# a34g43x register map
Vendor: ABOV Semiconductor Co., Ltd.; File version: 1.0
CPU: CM4 r0p1, little endian, MPU, FPU, VTOR, 4 interrupt priority bits
Registers are 32-bit, read-write, reset 0x0 unless marked. A register's access mark holds for its fields unless they carry their own. Offsets are from the block's base; [hi:lo] are bit positions; {n}, {i} and the like mark numbered series.

## I2C — Inter-Integrated Circuit
Base 0x5000A000
Same registers: I2C0 0x4000A000, I2C1 0x4000A100, I2C2 0x4000A200, I2C3 0x4000A300
0x00 DR reset 0xFF — I2Cn Data Register
  [7:0] ICDR — The I2CnDR Transmit buffer and Receive buffer share the same I/O address with this DATA register. The Transmit Data Buffer is the destination for data written to the I2CnDR register. Reading the I2CnDR register returns the contents of the Receive Buffer.
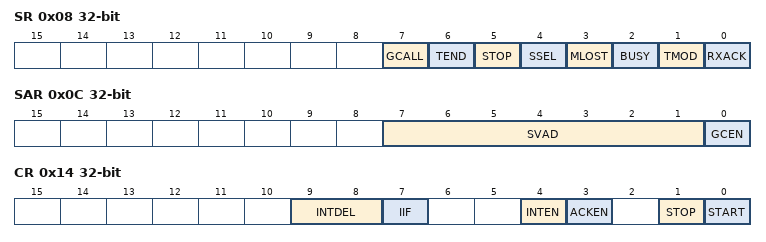
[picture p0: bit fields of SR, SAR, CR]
0x08 SR — I2Cn Status Register
  [7] GCALL — This bit has different meaning depending on whether I2C is master or slave. When I2C is a master, this bit represents whether it received AACK (address ACK) from slave.
  [6] TEND — This bit is set when 1-byte of data is transferred completely.
  [5] STOP — This bit is set when a STOP condition is detected.
  [4] SSEL — This bit is set when I2C is addressed by other master.
  [3] MLOST — This bit represents the result of bus arbitration in master mode.
  [2] BUSY — This bit reflects bus status.
  [1] TMOD ro — This bit is used to indicate whether I2C is transmitter or receiver.
  [0] RXACK — This bit shows the state of ACK signal.
0x0C SAR — I2Cn Slave Address Register
  [7:1] SVAD — These bits configure the slave address in slave mode.
  [0] GCEN — This bit decides whether I2Cn allows general call address 0 or not in I2Cn slave mode.
0x14 CR — I2Cn Control Register
  [9:8] INTDEL — between Address and Transmit data delay
    0=1_ICnSCLL (Delay = 1*ICnSCLL); 1=2_ICnSCLL (Delay = 2*ICnSCLL); 2=4_ICnSCLL (Delay = 4*ICnSCLL); 3=8_ICnSCLL (Delay = 8*ICnSCLL)
  [7] IIF ro — I2Cn Interrupt Flag bit. This bit is cleared when write any values in the I2CnST register.
  [4] INTEN — Interrupt Enable bit
  [3] ACKEN — received mode ACK allow bit
  [1] STOP — STOP Condition Generation When I2Cn is master.
  [0] START — START Condition Generation When I2Cn is master.
0x18 SCLL reset 0xFFFF — I2Cn SCL Low Period Register
  [15:0] SCLL — This register defines the low period of SCL in master mode. The base clock is PCLK and the period is calculated by the formula: tPCLK X (4 X I2CnSCLR + 2) where tPCLK is the period of PCLK.
0x1C SCLH reset 0xFFFF — I2Cn SCL High Period Register
  [15:0] SCLH — SCLH Value
0x20 SDH reset 0x7FFF — I2Cn SCL Hold Time Register
  [14:0] SDH — SDH Value

## CMP — Comparator
Base 0x5000B380
Same registers: CMP0 0x4000B380, CMP1 0x4000B390, CMP2 0x4000B3A0, CMP3 0x4000B3B0
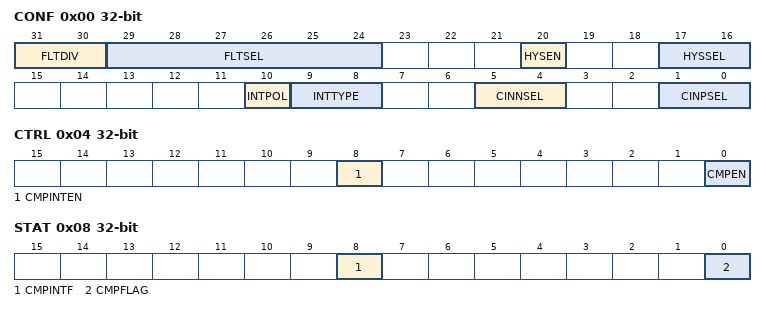
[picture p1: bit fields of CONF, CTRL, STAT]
0x00 CONF — Comparator 0 Configuration Register
  [31:30] FLTDIV — Digital filter clock divider
  [29:24] FLTSEL — Filter Counter Bit Selection
  [20] HYSEN — Comparator Hysteresis Enable Bit
    0=Disable; 1=Enable
  [17:16] HYSSEL — Comparator Hysteresis Selection Bit
    0=40mV Hysteresis; 1=80mV Hysteresis; 2=120mV Hysteresis; 3=160mV Hysteresis
  [10] INTPOL — Interrupt Polarity Selection Bit
    0=Low; 1=High
  [9:8] INTTYPE — Interrupt Type Selection Bit
    0=Disable; 1=Level; 2=Single_Edge; 3=Both_Edge
  [5:4] CINNSEL — Comparator Reference (Input) Selection Bit
    {v}=Reference{v} (Comparator Reference {v}) (v=0..3)
  [1:0] CINPSEL — Comparator Input (Input) Selection Bit
    {v}=Input{v} (Comparator Input {v}) (v=0..3)
0x04 CTRL — Comparator 0 Control Register
  [8] CMPINTEN — Comparator Interrupt Enable Bit
    0=Disable; 1=Enable
  [0] CMPEN — Comparator Enable Bit
    0=Disable; 1=Enable
0x08 STAT — Comparator 0 Status Register
  [8] CMPINTF — Comparator Interrupt Flag Bit
    0=Disables; 1=Enables
  [0] CMPFLAG ro — Comparator Output Flag
    0=Disables; 1=Enables

## DAC — Digital-to-Analog Converter
Base 0x5000B600
Same registers: DAC0 0x4000B600, DAC1 0x4000B700
0x00 DR — DAC n Data register
  [11:0] DACD — D/A Converter Data
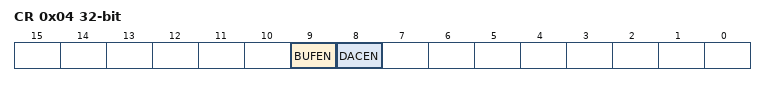
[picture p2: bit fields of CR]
0x04 CR — DAC Control register
  [9] BUFEN — DAC Buffer Enable Bit
  [8] DACEN — DAC Enable Bit
